AUTOSAR XML (schema 321)
package /ComponentType
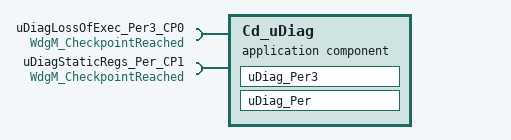
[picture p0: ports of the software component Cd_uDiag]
  application software component type Cd_uDiag
    require port uDiagLossOfExec_Per3_CP0: client-com-spec=CheckpointReached, required-interface=WdgM_CheckpointReached
    require port uDiagStaticRegs_Per_CP1: client-com-spec=CheckpointReached, required-interface=WdgM_CheckpointReached
  internal behavior Cd_uDiag_InternalBehavior: component=Cd_uDiag
    port-api-options:
      enable-take-address=false, indirect-api=false, port=uDiagLossOfExec_Per3_CP0
      enable-take-address=false, indirect-api=false, port=uDiagStaticRegs_Per_CP1
    runnable uDiag_Per3
      sync call SC_uDiagLossOfExec_Per3_CP0_CheckpointReached: operation=uDiagLossOfExec_Per3_CP0.CheckpointReached, timeout=0
    runnable uDiag_Per
      sync call SC_uDiagStaticRegs_Per_CP1_CheckpointReached: operation=uDiagStaticRegs_Per_CP1.CheckpointReached, timeout=0
  swc implementation Cd_uDiag_Implementation: behavior=Cd_uDiag_InternalBehavior
    code-descriptors:
      code Code: type=SRC
package /PortInterface
  client server interface WdgM_CheckpointReached: is-service=true
    operation CheckpointReached: possible-error=E_NOT_OK  # Indicates to the Watchdog Manager that a Checkpoint within a Supervised Entity has been reached.
    error E_NOT_OK: error-code=1
